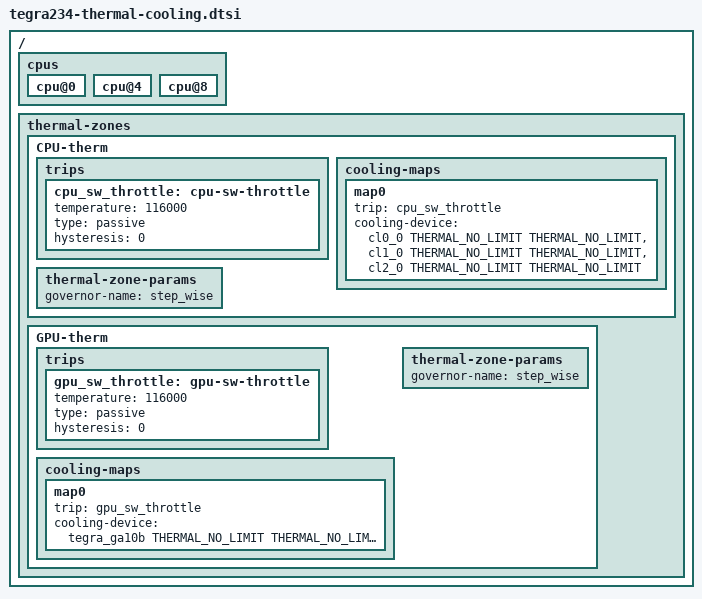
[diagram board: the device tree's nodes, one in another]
/*
 * Copyright (c) 2021, NVIDIA CORPORATION.  All rights reserved.
 *
 * This program is free software; you can redistribute it and/or modify it
 * under the terms and conditions of the GNU General Public License,
 * version 2, as published by the Free Software Foundation.
 *
 * This program is distributed in the hope it will be useful, but WITHOUT
 * ANY WARRANTY; without even the implied warranty of MERCHANTABILITY or
 * FITNESS FOR A PARTICULAR PURPOSE.  See the GNU General Public License for
 * more details.
 *
 * You should have received a copy of the GNU General Public License
 * along with this program.  If not, see <http://www.gnu.org/licenses/>.
 */

/ {
	cpus {
		cpu@0 {
			#cooling-cells = <2>;
		};
		cpu@4 {
			#cooling-cells = <2>;
		};
		cpu@8 {
			#cooling-cells = <2>;
		};
	};

	thermal-zones {
		CPU-therm {
			trips {
			cpu_sw_throttle: cpu-sw-throttle {
					temperature = <116000>;
					type = "passive";
					hysteresis = <0>;
				};

			};
			cooling-maps {
				map0 {
					trip = <&cpu_sw_throttle>;
					cooling-device = <&cl0_0 THERMAL_NO_LIMIT THERMAL_NO_LIMIT>,
							 <&cl1_0 THERMAL_NO_LIMIT THERMAL_NO_LIMIT>,
							 <&cl2_0 THERMAL_NO_LIMIT THERMAL_NO_LIMIT>;
				};
			};
			thermal-zone-params {
				governor-name = "step_wise";
			};
		};

		GPU-therm {
			trips {
			gpu_sw_throttle: gpu-sw-throttle {
					temperature = <116000>;
					type = "passive";
					hysteresis = <0>;
				};
			};
			cooling-maps {
				map0 {
					trip = <&gpu_sw_throttle>;
					cooling-device = <&tegra_ga10b THERMAL_NO_LIMIT THERMAL_NO_LIMIT>;
				};
			};
			thermal-zone-params {
				governor-name = "step_wise";
			};
		};
	};
};
